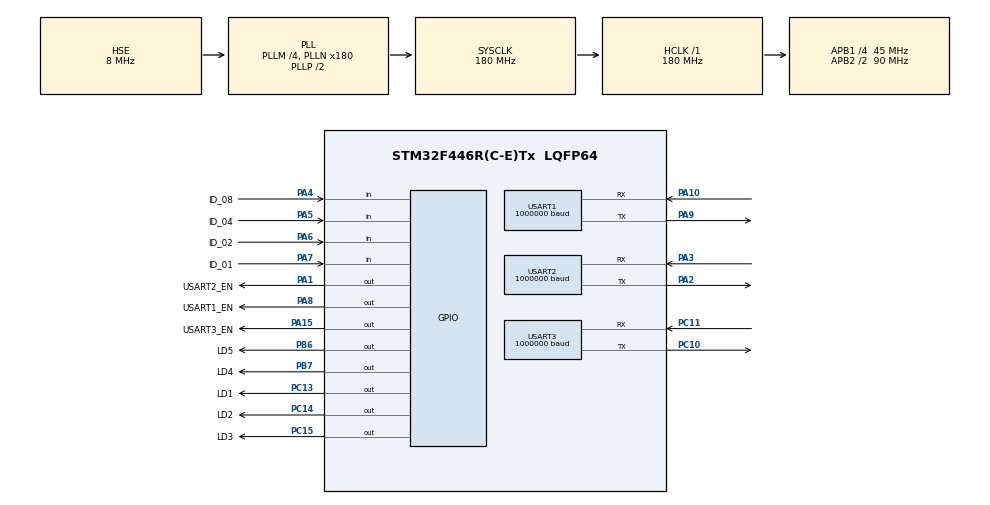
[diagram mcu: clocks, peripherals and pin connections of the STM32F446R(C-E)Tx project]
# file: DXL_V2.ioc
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FREERTOS.Queues01=okQueue,16,uint16_t,0,Dynamic,NULL,NULL;moveQueue,16,move_typedef,0,Dynamic,NULL,NULL
FREERTOS.Tasks01=defaultTask,24,128,StartDefaultTask,Default,NULL,Dynamic,NULL,NULL;dxlTask,47,1024,dxl_main,As weak,NULL,Dynamic,NULL,NULL;scheduleTask,45,1024,schedule_main,As weak,NULL,Dynamic,NULL,NULL
FREERTOS.configTOTAL_HEAP_SIZE=20480
FREERTOS.configUSE_NEWLIB_REENTRANT=1
Mcu.Family=STM32F4
Mcu.Name=STM32F446R(C-E)Tx
Mcu.Package=LQFP64
NVIC.PriorityGroup=NVIC_PRIORITYGROUP_4
NVIC.TIM4_IRQn=true\:15\:0\:false\:false\:true\:false\:false\:true\:true
NVIC.TimeBase=TIM4_IRQn
NVIC.TimeBaseIP=TIM4
NVIC.USART1_IRQn=true\:5\:0\:false\:false\:true\:true\:true\:true\:true
NVIC.USART2_IRQn=true\:5\:0\:false\:false\:true\:true\:true\:true\:true
NVIC.USART3_IRQn=true\:5\:0\:false\:false\:true\:true\:true\:true\:true
PA1.GPIO_Label=USART2_EN
PA1.GPIO_Speed=GPIO_SPEED_FREQ_VERY_HIGH
PA1.Signal=GPIO_Output
PA10.Mode=Asynchronous
PA10.Signal=USART1_RX
PA11.Signal=CAN1_RX
PA13.Mode=Serial_Wire
PA13.Signal=SYS_JTMS-SWDIO
PA14.Mode=Serial_Wire
PA14.Signal=SYS_JTCK-SWCLK
PA15.GPIO_Label=USART3_EN
PA15.GPIO_Speed=GPIO_SPEED_FREQ_VERY_HIGH
PA15.Signal=GPIO_Output
PA2.Mode=Asynchronous
PA2.Signal=USART2_TX
PA3.Mode=Asynchronous
PA3.Signal=USART2_RX
PA4.GPIO_Label=ID_08
PA4.Signal=GPIO_Input
PA5.GPIO_Label=ID_04
PA5.Signal=GPIO_Input
PA6.GPIO_Label=ID_02
PA6.Signal=GPIO_Input
PA7.GPIO_Label=ID_01
PA7.Signal=GPIO_Input
PA8.GPIO_Label=USART1_EN
PA8.GPIO_Speed=GPIO_SPEED_FREQ_VERY_HIGH
PA8.Signal=GPIO_Output
PA9.Mode=Asynchronous
PA9.Signal=USART1_TX
PB6.GPIO_Label=LD5
PB6.Signal=GPIO_Output
PB7.GPIO_Label=LD4
PB7.Signal=GPIO_Output
PC10.Mode=Asynchronous
PC10.Signal=USART3_TX
PC11.Mode=Asynchronous
PC11.Signal=USART3_RX
PC13.GPIO_Label=LD1
PC13.Signal=GPIO_Output
PC14-OSC32_IN.GPIO_Label=LD2
PC14-OSC32_IN.Signal=GPIO_Output
PC15-OSC32_OUT.GPIO_Label=LD3
PC15-OSC32_OUT.Signal=GPIO_Output
PH0-OSC_IN.Mode=HSE-External-Oscillator
PH0-OSC_IN.Signal=RCC_OSC_IN
PH1-OSC_OUT.Mode=HSE-External-Oscillator
PH1-OSC_OUT.Signal=RCC_OSC_OUT
ProjectManager.HeapSize=0x200
ProjectManager.StackSize=0x400
ProjectManager.TargetToolchain=STM32CubeIDE
RCC.AHBFreq_Value=180000000
RCC.APB1CLKDivider=RCC_HCLK_DIV4
RCC.APB1Freq_Value=45000000
RCC.APB1TimFreq_Value=90000000
RCC.APB2CLKDivider=RCC_HCLK_DIV2
RCC.APB2Freq_Value=90000000
RCC.APB2TimFreq_Value=180000000
RCC.CortexFreq_Value=180000000
RCC.HCLKFreq_Value=180000000
RCC.HSE_VALUE=8000000
RCC.PLLM=4
RCC.PLLN=180
RCC.PLLSourceVirtual=RCC_PLLSOURCE_HSE
RCC.SYSCLKFreq_VALUE=180000000
RCC.SYSCLKSource=RCC_SYSCLKSOURCE_PLLCLK
RCC.USBFreq_Value=180000000
RCC.VCOOutputFreq_Value=360000000
USART1.BaudRate=1000000
USART1.VirtualMode=VM_ASYNC
USART2.BaudRate=1000000
USART2.VirtualMode=VM_ASYNC
USART3.BaudRate=1000000
USART3.VirtualMode=VM_ASYNC
VP_FREERTOS_VS_CMSIS_V2.Mode=CMSIS_V2
VP_SYS_VS_tim4.Mode=TIM4
board=custom

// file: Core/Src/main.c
/* USER CODE BEGIN Header */
/**
  ******************************************************************************
  * @file           : main.c
  * @brief          : Main program body
  ******************************************************************************
  * @attention
  *
  * Copyright (c) 2024 STMicroelectronics.
  * All rights reserved.
  *
  * This software is licensed under terms that can be found in the LICENSE file
  * in the root directory of this software component.
  * If no LICENSE file comes with this software, it is provided AS-IS.
  *
  ******************************************************************************
  */
/* USER CODE END Header */
#include "main.h"
#include "cmsis_os.h"
#include "usart.h"
#include "gpio.h"

void SystemClock_Config(void);
void MX_FREERTOS_Init(void);

int main(void)
{

  /* MCU Configuration--------------------------------------------------------*/

  /* Reset of all peripherals, Initializes the Flash interface and the Systick. */
  HAL_Init();

  /* Configure the system clock */
  SystemClock_Config();

  /* Initialize all configured peripherals */
  MX_GPIO_Init();
  MX_USART1_UART_Init();
  MX_USART2_UART_Init();
  MX_USART3_UART_Init();

  /* Init scheduler */
  osKernelInitialize();

  /* Call init function for freertos objects (in freertos.c) */
  MX_FREERTOS_Init();

  /* Start scheduler */
  osKernelStart();

  /* We should never get here as control is now taken by the scheduler */
  /* Infinite loop */
  while (1)
  {

  }
}

void SystemClock_Config(void)
{
  RCC_OscInitTypeDef RCC_OscInitStruct = {0};
  RCC_ClkInitTypeDef RCC_ClkInitStruct = {0};

  /** Configure the main internal regulator output voltage
  */
  __HAL_RCC_PWR_CLK_ENABLE();
  __HAL_PWR_VOLTAGESCALING_CONFIG(PWR_REGULATOR_VOLTAGE_SCALE1);

  /** Initializes the RCC Oscillators according to the specified parameters
  * in the RCC_OscInitTypeDef structure.
  */
  RCC_OscInitStruct.OscillatorType = RCC_OSCILLATORTYPE_HSE;
  RCC_OscInitStruct.HSEState = RCC_HSE_ON;
  RCC_OscInitStruct.PLL.PLLState = RCC_PLL_ON;
  RCC_OscInitStruct.PLL.PLLSource = RCC_PLLSOURCE_HSE;
  RCC_OscInitStruct.PLL.PLLM = 4;
  RCC_OscInitStruct.PLL.PLLN = 180;
  RCC_OscInitStruct.PLL.PLLP = RCC_PLLP_DIV2;
  RCC_OscInitStruct.PLL.PLLQ = 2;
  RCC_OscInitStruct.PLL.PLLR = 2;
  if (HAL_RCC_OscConfig(&RCC_OscInitStruct) != HAL_OK)
  {
    Error_Handler();
  }

  /** Activate the Over-Drive mode
  */
  if (HAL_PWREx_EnableOverDrive() != HAL_OK)
  {
    Error_Handler();
  }

  /** Initializes the CPU, AHB and APB buses clocks
  */
  RCC_ClkInitStruct.ClockType = RCC_CLOCKTYPE_HCLK|RCC_CLOCKTYPE_SYSCLK
                              |RCC_CLOCKTYPE_PCLK1|RCC_CLOCKTYPE_PCLK2;
  RCC_ClkInitStruct.SYSCLKSource = RCC_SYSCLKSOURCE_PLLCLK;
  RCC_ClkInitStruct.AHBCLKDivider = RCC_SYSCLK_DIV1;
  RCC_ClkInitStruct.APB1CLKDivider = RCC_HCLK_DIV4;
  RCC_ClkInitStruct.APB2CLKDivider = RCC_HCLK_DIV2;

  if (HAL_RCC_ClockConfig(&RCC_ClkInitStruct, FLASH_LATENCY_5) != HAL_OK)
  {
    Error_Handler();
  }
}

void HAL_TIM_PeriodElapsedCallback(TIM_HandleTypeDef *htim)
{
  if (htim->Instance == TIM4) {
    HAL_IncTick();
  }
}

void Error_Handler(void)
{
  __disable_irq();
  while (1)
  {
  }
}

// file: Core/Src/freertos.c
/* USER CODE BEGIN Header */
/**
  ******************************************************************************
  * File Name          : freertos.c
  * Description        : Code for freertos applications
  ******************************************************************************
  * @attention
  *
  * Copyright (c) 2024 STMicroelectronics.
  * All rights reserved.
  *
  * This software is licensed under terms that can be found in the LICENSE file
  * in the root directory of this software component.
  * If no LICENSE file comes with this software, it is provided AS-IS.
  *
  ******************************************************************************
  */
/* USER CODE END Header */

#include "FreeRTOS.h"
#include "task.h"
#include "main.h"
#include "cmsis_os.h"

/* USER CODE BEGIN Includes */
#include "dxl_main.h"
#include "schedule_main.h"
/* USER CODE END Includes */

/* Definitions for defaultTask */
osThreadId_t defaultTaskHandle;
const osThreadAttr_t defaultTask_attributes = {
  .name = "defaultTask",
  .stack_size = 128 * 4,
  .priority = (osPriority_t) osPriorityNormal,
};
/* Definitions for dxlTask */
osThreadId_t dxlTaskHandle;
const osThreadAttr_t dxlTask_attributes = {
  .name = "dxlTask",
  .stack_size = 1024 * 4,
  .priority = (osPriority_t) osPriorityHigh7,
};
/* Definitions for scheduleTask */
osThreadId_t scheduleTaskHandle;
const osThreadAttr_t scheduleTask_attributes = {
  .name = "scheduleTask",
  .stack_size = 1024 * 4,
  .priority = (osPriority_t) osPriorityHigh5,
};
/* Definitions for okQueue */
osMessageQueueId_t okQueueHandle;
const osMessageQueueAttr_t okQueue_attributes = {
  .name = "okQueue"
};
/* Definitions for moveQueue */
osMessageQueueId_t moveQueueHandle;
const osMessageQueueAttr_t moveQueue_attributes = {
  .name = "moveQueue"
};

void StartDefaultTask(void *argument);
void dxl_main(void *argument);
void schedule_main(void *argument);

void MX_FREERTOS_Init(void); /* (MISRA C 2004 rule 8.1) */

void MX_FREERTOS_Init(void) {

  /* Create the queue(s) */
  /* creation of okQueue */
  okQueueHandle = osMessageQueueNew (16, sizeof(uint16_t), &okQueue_attributes);

  /* creation of moveQueue */
  moveQueueHandle = osMessageQueueNew (16, sizeof(move_typedef), &moveQueue_attributes);

  /* Create the thread(s) */
  /* creation of defaultTask */
  defaultTaskHandle = osThreadNew(StartDefaultTask, NULL, &defaultTask_attributes);

  /* creation of dxlTask */
  dxlTaskHandle = osThreadNew(dxl_main, NULL, &dxlTask_attributes);

  /* creation of scheduleTask */
  scheduleTaskHandle = osThreadNew(schedule_main, NULL, &scheduleTask_attributes);

}

void StartDefaultTask(void *argument)
{
  for(;;)
  {
    osDelay(1);
  }
}

__weak void dxl_main(void *argument)
{
  for(;;)
  {
    osDelay(1);
  }
}

__weak void schedule_main(void *argument)
{
  for(;;)
  {
    osDelay(1);
  }
}
